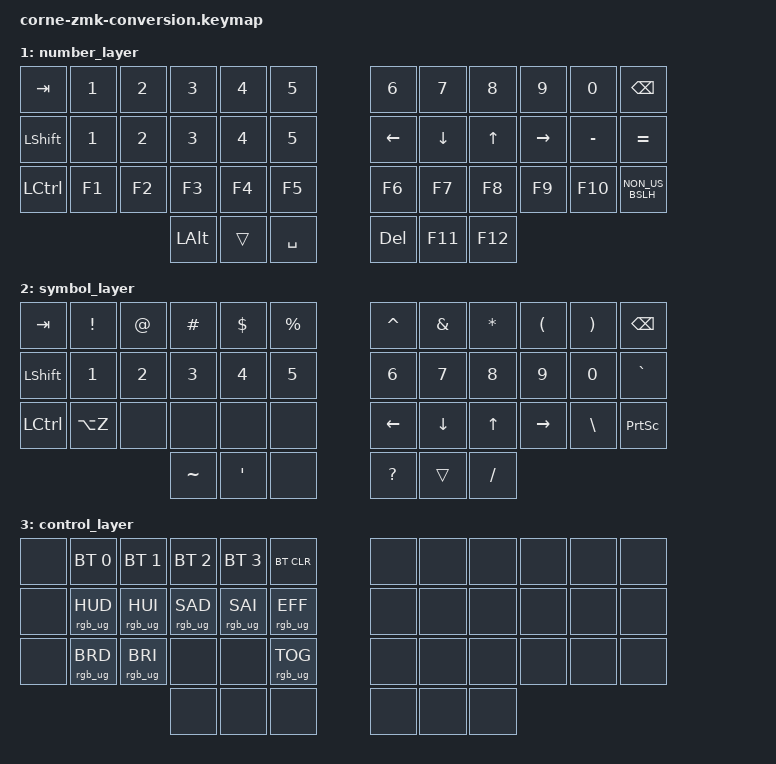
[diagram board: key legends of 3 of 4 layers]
/*
 * Corne (CRKBD) v4 ZMK Keymap
 * Converted from Vial configuration
 * Date: 2025-02-18
 */

#include <behaviors.dtsi>
#include <dt-bindings/zmk/keys.h>
#include <dt-bindings/zmk/bt.h>
#include <dt-bindings/zmk/rgb.h>
#include <dt-bindings/zmk/ext_power.h>

/ {
    behaviors {
        // Home row mods
        hm: homerow_mods {
            compatible = "zmk,behavior-hold-tap";
            #binding-cells = <2>;
            tapping-term-ms = <150>;
            quick-tap-ms = <0>;
            flavor = "tap-preferred";
            bindings = <&kp>, <&kp>;
        };

        // Tap dance for F12/F5 (converted from TD(0))
        td_f12_f5: tap_dance_f12_f5 {
            compatible = "zmk,behavior-tap-dance";
            #binding-cells = <0>;
            tapping-term-ms = <200>;
            bindings = <&kp F12>, <&kp F5>;
        };

        // GUI when held, Alt when tapped (converted from LGUI_T(KC_LALT))
        gmt: gui_mod_tap {
            compatible = "zmk,behavior-hold-tap";
            #binding-cells = <2>;
            flavor = "tap-preferred";
            tapping-term-ms = <150>;
            quick-tap-ms = <0>;
            bindings = <&kp>, <&kp>;
        };
    };

    macros {
        // Alt+Tab macro (converted from your Vial macro)
        alt_tab: alt_tab {
            compatible = "zmk,behavior-macro";
            #binding-cells = <0>;
            bindings = <&macro_press &kp LALT>, <&macro_tap &kp TAB>, <&macro_release &kp LALT>;
        };
    };

    keymap {
        compatible = "zmk,keymap";

        // Layer 0 - Base QWERTY Layer
        base_layer {
            bindings = <
//    ┌───────────┬───────────┬───────────┬───────────┬───────────┬───────────┐                    ┌───────────┬───────────┬───────────┬───────────┬───────────┬───────────┐
      &kp TAB     &kp Q       &kp W       &kp E       &kp R       &kp T                             &kp Y       &kp U       &kp I       &kp O       &kp P       &kp BSPC
//    ├───────────┼───────────┼───────────┼───────────┼───────────┼───────────┤                    ├───────────┼───────────┼───────────┼───────────┼───────────┼───────────┤
      &kp LSHFT   &kp A       &kp S       &kp D       &kp F       &kp G                             &kp H       &kp J       &kp K       &kp L       &kp SEMI    &kp SQT
//    ├───────────┼───────────┼───────────┼───────────┼───────────┼───────────┤                    ├───────────┼───────────┼───────────┼───────────┼───────────┼───────────┤
      &kp LCTRL   &kp Z       &kp X       &kp C       &kp V       &kp B                             &kp N       &kp M       &kp COMMA   &kp DOT     &kp FSLH    &kp RSHFT
//    └───────────┴───────────┴───────────┼───────────┼───────────┼───────────┤                    ├───────────┼───────────┼───────────┼───────────┴───────────┴───────────┘
                                          &gmt LGUI LALT &mo 1    &kp SPACE                         &kp LSHFT &kp RET &mo 2 &kp RALT
//                                        └───────────┴───────────┴───────────┘                    └───────────┴───────────┴───────────┘
            >;
            sensor-bindings = <&inc_dec_kp C_VOL_UP C_VOL_DN>;
        };

        // Layer 1 - Numbers and Function Keys
        number_layer {
            bindings = <
//    ┌───────────┬───────────┬───────────┬───────────┬───────────┬───────────┐                    ┌───────────┬───────────┬───────────┬───────────┬───────────┬───────────┐
      &kp TAB     &kp N1      &kp N2      &kp N3      &kp N4      &kp N5                            &kp N6      &kp N7      &kp N8      &kp N9      &kp N0      &kp BSPC
//    ├───────────┼───────────┼───────────┼───────────┼───────────┼───────────┤                    ├───────────┼───────────┼───────────┼───────────┼───────────┼───────────┤
      &kp LSHFT   &kp N1      &kp N2      &kp N3      &kp N4      &kp N5                            &kp LEFT    &kp DOWN    &kp UP      &kp RIGHT   &kp MINUS   &kp EQUAL
//    ├───────────┼───────────┼───────────┼───────────┼───────────┼───────────┤                    ├───────────┼───────────┼───────────┼───────────┼───────────┼───────────┤
      &kp LCTRL   &kp F1      &kp F2      &kp F3      &kp F4      &kp F5                            &kp F6      &kp F7      &kp F8      &kp F9      &kp F10     &kp NON_US_BSLH
//    └───────────┴───────────┴───────────┼───────────┼───────────┼───────────┤                    ├───────────┼───────────┼───────────┼───────────┴───────────┴───────────┘
                                          &kp LALT    &trans      &kp SPACE                         &kp DEL     &kp F11     &kp F12
//                                        └───────────┴───────────┴───────────┘                    └───────────┴───────────┴───────────┘
            >;
            sensor-bindings = <&inc_dec_kp C_VOL_UP C_VOL_DN>;
        };

        // Layer 2 - Symbols and Special Characters
        symbol_layer {
            bindings = <
//    ┌───────────┬───────────┬───────────┬───────────┬───────────┬───────────┐                    ┌───────────┬───────────┬───────────┬───────────┬───────────┬───────────┐
      &kp TAB     &kp EXCL    &kp AT      &kp HASH    &kp DLLR    &kp PRCNT                         &kp CARET   &kp AMPS    &kp ASTRK   &kp LPAR    &kp RPAR    &kp BSPC
//    ├───────────┼───────────┼───────────┼───────────┼───────────┼───────────┤                    ├───────────┼───────────┼───────────┼───────────┼───────────┼───────────┤
      &kp LSHFT   &kp N1      &kp N2      &kp N3      &kp N4      &kp N5                            &kp N6      &kp N7      &kp N8      &kp N9      &kp N0      &kp GRAVE
//    ├───────────┼───────────┼───────────┼───────────┼───────────┼───────────┤                    ├───────────┼───────────┼───────────┼───────────┼───────────┼───────────┤
      &kp LCTRL   &kp LA(Z)   &none       &none       &none       &none                             &kp LEFT    &kp DOWN    &kp UP      &kp RIGHT   &kp BSLH    &kp PSCRN
//    └───────────┴───────────┴───────────┼───────────┼───────────┼───────────┤                    ├───────────┼───────────┼───────────┼───────────┴───────────┴───────────┘
                                          &kp TILDE   &kp SQT     &none                             &kp QMARK   &trans      &kp FSLH
//                                        └───────────┴───────────┴───────────┘                    └───────────┴───────────┴───────────┘
            >;
            sensor-bindings = <&inc_dec_kp C_VOL_UP C_VOL_DN>;
        };

        // Layer 3 - RGB and Bluetooth Controls  
        control_layer {
            bindings = <
//    ┌───────────┬───────────┬───────────┬───────────┬───────────┬───────────┐                    ┌───────────┬───────────┬───────────┬───────────┬───────────┬───────────┐
      &none       &bt BT_SEL 0 &bt BT_SEL 1 &bt BT_SEL 2 &bt BT_SEL 3 &bt BT_CLR                  &none       &none       &none       &none       &none       &none
//    ├───────────┼───────────┼───────────┼───────────┼───────────┼───────────┤                    ├───────────┼───────────┼───────────┼───────────┼───────────┼───────────┤
      &none       &rgb_ug RGB_HUD &rgb_ug RGB_HUI &rgb_ug RGB_SAD &rgb_ug RGB_SAI &rgb_ug RGB_EFF      &none       &none       &none       &none       &none       &none
//    ├───────────┼───────────┼───────────┼───────────┼───────────┼───────────┤                    ├───────────┼───────────┼───────────┼───────────┼───────────┼───────────┤
      &none       &rgb_ug RGB_BRD &rgb_ug RGB_BRI &none &none    &rgb_ug RGB_TOG                   &none       &none       &none       &none       &none       &none
//    └───────────┴───────────┴───────────┼───────────┼───────────┼───────────┤                    ├───────────┼───────────┼───────────┼───────────┴───────────┴───────────┘
                                          &none       &none       &none                             &none       &none       &none
//                                        └───────────┴───────────┴───────────┘                    └───────────┴───────────┴───────────┘
            >;
            sensor-bindings = <&inc_dec_kp RGB_HUI RGB_HUD>;
        };
    };
};

// Encoder mappings for different layers
&left_encoder { resolution = <4>; };
&right_encoder { resolution = <4>; };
